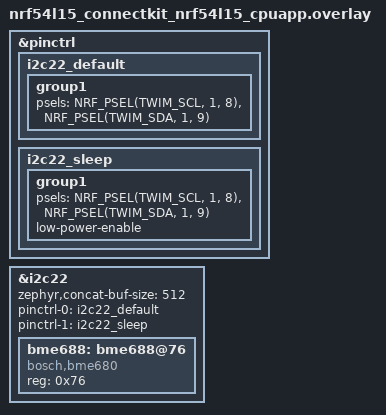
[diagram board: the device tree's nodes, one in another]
/*
 * Copyright 2024 Nordic Semiconductor ASA
 * SPDX-License-Identifier: Apache-2.0
 */

&pinctrl {
	i2c22_default: i2c22_default {
		group1  {
			psels = <NRF_PSEL(TWIM_SCL, 1, 8)>,
					<NRF_PSEL(TWIM_SDA, 1, 9)>;
		};
	};

	i2c22_sleep: i2c22_sleep {
		group1  {
			psels = <NRF_PSEL(TWIM_SCL, 1, 8)>,
					<NRF_PSEL(TWIM_SDA, 1, 9)>;
			low-power-enable;
		};
	};
};

&i2c22 {
	status = "okay";
	zephyr,concat-buf-size = <512>;
	pinctrl-0 = <&i2c22_default>;
	pinctrl-1 = <&i2c22_sleep>;
	pinctrl-names = "default", "sleep";

	bme688: bme688@76 {
		compatible = "bosch,bme680";
		status = "okay";
		reg = <0x76>;
	};
};
